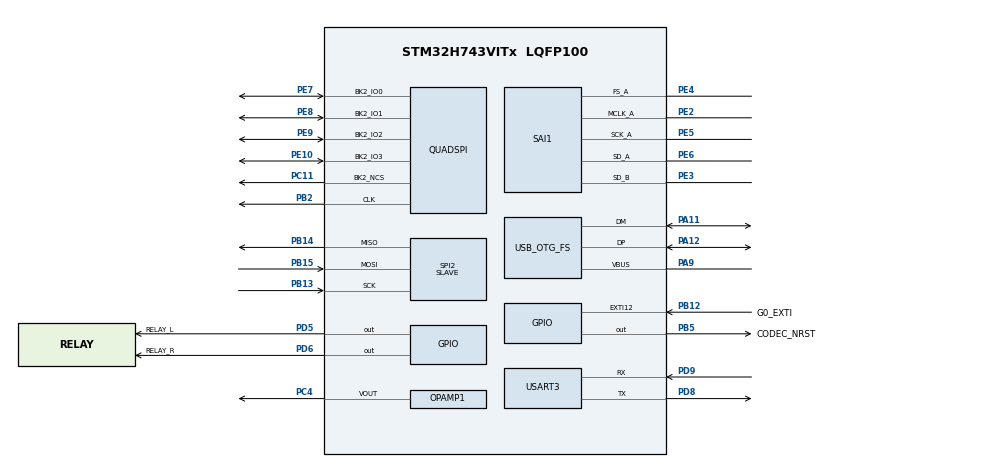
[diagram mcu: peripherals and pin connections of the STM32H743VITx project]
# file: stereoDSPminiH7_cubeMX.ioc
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CORTEX_M7.AccessPermission_S-Cortex_Memory_Protection_Unit_Region1_Settings_S=MPU_REGION_PRIV_RO
CORTEX_M7.AccessPermission_S-Cortex_Memory_Protection_Unit_Region2_Settings_S=MPU_REGION_FULL_ACCESS
CORTEX_M7.AccessPermission_S-Cortex_Memory_Protection_Unit_Region3_Settings_S=MPU_REGION_FULL_ACCESS
CORTEX_M7.BaseAddress_S-Cortex_Memory_Protection_Unit_Region1_Settings_S=0x08000000
CORTEX_M7.BaseAddress_S-Cortex_Memory_Protection_Unit_Region2_Settings_S=0x30046000
CORTEX_M7.BaseAddress_S-Cortex_Memory_Protection_Unit_Region3_Settings_S=0x90000000
CORTEX_M7.CPU_DCache=Enabled
CORTEX_M7.CPU_ICache=Enabled
CORTEX_M7.Enable_S-Cortex_Memory_Protection_Unit_Region1_Settings_S=MPU_REGION_ENABLE
CORTEX_M7.Enable_S-Cortex_Memory_Protection_Unit_Region2_Settings_S=MPU_REGION_ENABLE
CORTEX_M7.Enable_S-Cortex_Memory_Protection_Unit_Region3_Settings_S=MPU_REGION_ENABLE
CORTEX_M7.IsBufferable_S-Cortex_Memory_Protection_Unit_Region1_Settings_S=MPU_ACCESS_BUFFERABLE
CORTEX_M7.IsCacheable_S-Cortex_Memory_Protection_Unit_Region1_Settings_S=MPU_ACCESS_CACHEABLE
CORTEX_M7.Number_S-Cortex_Memory_Protection_Unit_Region2_Settings_S=MPU_REGION_NUMBER2
CORTEX_M7.Number_S-Cortex_Memory_Protection_Unit_Region3_Settings_S=MPU_REGION_NUMBER3
CORTEX_M7.Size_S-Cortex_Memory_Protection_Unit_Region1_Settings_S=MPU_REGION_SIZE_2MB
CORTEX_M7.Size_S-Cortex_Memory_Protection_Unit_Region2_Settings_S=MPU_REGION_SIZE_8KB
CORTEX_M7.Size_S-Cortex_Memory_Protection_Unit_Region3_Settings_S=MPU_REGION_SIZE_16MB
CORTEX_M7.TypeExtField_S-Cortex_Memory_Protection_Unit_Region1_Settings_S=MPU_TEX_LEVEL1
CORTEX_M7.TypeExtField_S-Cortex_Memory_Protection_Unit_Region2_Settings_S=MPU_TEX_LEVEL1
CORTEX_M7.TypeExtField_S-Cortex_Memory_Protection_Unit_Region3_Settings_S=MPU_TEX_LEVEL1
CORTEX_M7.default_mode_Activation=1
DAC1.DAC_Channel-DAC_OUT1_Int=DAC_CHANNEL_1
Dma.Request0=SAI1_A
Dma.Request1=SAI1_B
Dma.Request2=SPI2_RX
Dma.Request3=SPI2_TX
Dma.SAI1_A.0.Direction=DMA_MEMORY_TO_PERIPH
Dma.SAI1_A.0.EventEnable=DISABLE
Dma.SAI1_A.0.FIFOMode=DMA_FIFOMODE_ENABLE
Dma.SAI1_A.0.FIFOThreshold=DMA_FIFO_THRESHOLD_FULL
Dma.SAI1_A.0.Instance=DMA1_Stream0
Dma.SAI1_A.0.MemBurst=DMA_MBURST_INC4
Dma.SAI1_A.0.MemDataAlignment=DMA_MDATAALIGN_WORD
Dma.SAI1_A.0.MemInc=DMA_MINC_ENABLE
Dma.SAI1_A.0.Mode=DMA_CIRCULAR
Dma.SAI1_A.0.PeriphBurst=DMA_PBURST_INC4
Dma.SAI1_A.0.PeriphDataAlignment=DMA_PDATAALIGN_WORD
Dma.SAI1_A.0.PeriphInc=DMA_PINC_DISABLE
Dma.SAI1_A.0.Polarity=HAL_DMAMUX_REQ_GEN_RISING
Dma.SAI1_A.0.Priority=DMA_PRIORITY_VERY_HIGH
Dma.SAI1_A.0.RequestNumber=1
Dma.SAI1_A.0.SignalID=NONE
Dma.SAI1_A.0.SyncEnable=DISABLE
Dma.SAI1_A.0.SyncPolarity=HAL_DMAMUX_SYNC_NO_EVENT
Dma.SAI1_A.0.SyncRequestNumber=1
Dma.SAI1_A.0.SyncSignalID=NONE
Dma.SAI1_B.1.Direction=DMA_PERIPH_TO_MEMORY
Dma.SAI1_B.1.EventEnable=DISABLE
Dma.SAI1_B.1.FIFOMode=DMA_FIFOMODE_ENABLE
Dma.SAI1_B.1.FIFOThreshold=DMA_FIFO_THRESHOLD_FULL
Dma.SAI1_B.1.Instance=DMA1_Stream1
Dma.SAI1_B.1.MemBurst=DMA_MBURST_INC4
Dma.SAI1_B.1.MemDataAlignment=DMA_MDATAALIGN_WORD
Dma.SAI1_B.1.MemInc=DMA_MINC_ENABLE
Dma.SAI1_B.1.Mode=DMA_CIRCULAR
Dma.SAI1_B.1.PeriphBurst=DMA_PBURST_INC4
Dma.SAI1_B.1.PeriphDataAlignment=DMA_PDATAALIGN_WORD
Dma.SAI1_B.1.PeriphInc=DMA_PINC_DISABLE
Dma.SAI1_B.1.Polarity=HAL_DMAMUX_REQ_GEN_RISING
Dma.SAI1_B.1.Priority=DMA_PRIORITY_VERY_HIGH
Dma.SAI1_B.1.RequestNumber=1
Dma.SAI1_B.1.SignalID=NONE
Dma.SAI1_B.1.SyncEnable=DISABLE
Dma.SAI1_B.1.SyncPolarity=HAL_DMAMUX_SYNC_NO_EVENT
Dma.SAI1_B.1.SyncRequestNumber=1
Dma.SAI1_B.1.SyncSignalID=NONE
Dma.SPI2_RX.2.Direction=DMA_PERIPH_TO_MEMORY
Dma.SPI2_RX.2.EventEnable=DISABLE
Dma.SPI2_RX.2.FIFOMode=DMA_FIFOMODE_DISABLE
Dma.SPI2_RX.2.Instance=DMA2_Stream0
Dma.SPI2_RX.2.MemDataAlignment=DMA_MDATAALIGN_HALFWORD
Dma.SPI2_RX.2.MemInc=DMA_MINC_ENABLE
Dma.SPI2_RX.2.Mode=DMA_NORMAL
Dma.SPI2_RX.2.PeriphDataAlignment=DMA_PDATAALIGN_HALFWORD
Dma.SPI2_RX.2.PeriphInc=DMA_PINC_DISABLE
Dma.SPI2_RX.2.Polarity=HAL_DMAMUX_REQ_GEN_RISING
Dma.SPI2_RX.2.Priority=DMA_PRIORITY_VERY_HIGH
Dma.SPI2_RX.2.RequestNumber=1
Dma.SPI2_RX.2.SignalID=NONE
Dma.SPI2_RX.2.SyncEnable=DISABLE
Dma.SPI2_RX.2.SyncPolarity=HAL_DMAMUX_SYNC_NO_EVENT
Dma.SPI2_RX.2.SyncRequestNumber=1
Dma.SPI2_RX.2.SyncSignalID=NONE
Dma.SPI2_TX.3.Direction=DMA_MEMORY_TO_PERIPH
Dma.SPI2_TX.3.EventEnable=DISABLE
Dma.SPI2_TX.3.FIFOMode=DMA_FIFOMODE_DISABLE
Dma.SPI2_TX.3.Instance=DMA2_Stream1
Dma.SPI2_TX.3.MemDataAlignment=DMA_MDATAALIGN_HALFWORD
Dma.SPI2_TX.3.MemInc=DMA_MINC_ENABLE
Dma.SPI2_TX.3.Mode=DMA_NORMAL
Dma.SPI2_TX.3.PeriphDataAlignment=DMA_PDATAALIGN_HALFWORD
Dma.SPI2_TX.3.PeriphInc=DMA_PINC_DISABLE
Dma.SPI2_TX.3.Polarity=HAL_DMAMUX_REQ_GEN_RISING
Dma.SPI2_TX.3.Priority=DMA_PRIORITY_VERY_HIGH
Dma.SPI2_TX.3.RequestNumber=1
Dma.SPI2_TX.3.SignalID=NONE
Dma.SPI2_TX.3.SyncEnable=DISABLE
Dma.SPI2_TX.3.SyncPolarity=HAL_DMAMUX_SYNC_NO_EVENT
Dma.SPI2_TX.3.SyncRequestNumber=1
Dma.SPI2_TX.3.SyncSignalID=NONE
Mcu.Family=STM32H7
Mcu.Name=STM32H743VITx
Mcu.Package=LQFP100
NVIC.DMA1_Stream0_IRQn=true\:0\:0\:true\:false\:true\:false\:true\:true
NVIC.DMA1_Stream1_IRQn=true\:0\:0\:false\:false\:true\:false\:true\:true
NVIC.DMA2_Stream0_IRQn=true\:2\:0\:true\:false\:true\:false\:true\:true
NVIC.DMA2_Stream1_IRQn=true\:2\:0\:true\:false\:true\:false\:true\:true
NVIC.EXTI15_10_IRQn=true\:2\:0\:true\:false\:true\:true\:true\:true
NVIC.OTG_FS_EP1_IN_IRQn=true\:0\:0\:false\:false\:true\:true\:true\:true
NVIC.OTG_FS_EP1_OUT_IRQn=true\:0\:0\:false\:false\:true\:true\:true\:true
NVIC.OTG_FS_IRQn=true\:0\:0\:false\:false\:true\:false\:true\:true
NVIC.PriorityGroup=NVIC_PRIORITYGROUP_4
NVIC.SAI1_IRQn=true\:1\:0\:true\:false\:true\:true\:true\:true
NVIC.SPI2_IRQn=true\:2\:0\:true\:false\:true\:false\:true\:true
PA11.Mode=Device_Only
PA11.Signal=USB_OTG_FS_DM
PA12.Mode=Device_Only
PA12.Signal=USB_OTG_FS_DP
PA13\ (JTMS/SWDIO).Mode=Trace_Asynchronous_SW
PA13\ (JTMS/SWDIO).Signal=DEBUG_JTMS-SWDIO
PA14\ (JTCK/SWCLK).Mode=Trace_Asynchronous_SW
PA14\ (JTCK/SWCLK).Signal=DEBUG_JTCK-SWCLK
PA9.Mode=Activate_VBUS
PA9.Signal=USB_OTG_FS_VBUS
PB12.GPIO_Label=G0_EXTI
PB12.Signal=GPXTI12
PB13.Mode=Full_Duplex_Slave
PB13.Signal=SPI2_SCK
PB14.Mode=Full_Duplex_Slave
PB14.Signal=SPI2_MISO
PB15.Mode=Full_Duplex_Slave
PB15.Signal=SPI2_MOSI
PB2.GPIO_Speed=GPIO_SPEED_FREQ_HIGH
PB2.Mode=Single Bank 2
PB2.Signal=QUADSPI_CLK
PB3\ (JTDO/TRACESWO).Mode=Trace_Asynchronous_SW
PB3\ (JTDO/TRACESWO).Signal=DEBUG_JTDO-SWO
PB5.GPIO_Label=CODEC_NRST
PB5.Signal=GPIO_Output
PC11.GPIO_PuPd=GPIO_PULLUP
PC11.GPIO_Speed=GPIO_SPEED_FREQ_MEDIUM
PC11.Mode=Single Bank 2
PC11.Signal=QUADSPI_BK2_NCS
PC4.Mode=Follower-DAC_OUT1-INP
PC4.Signal=OPAMP1_VOUT
PD5.GPIO_Label=RELAY_L
PD5.Signal=GPIO_Output
PD6.GPIO_Label=RELAY_R
PD6.Signal=GPIO_Output
PD8.Mode=Asynchronous
PD8.Signal=USART3_TX
PD9.GPIO_PuPd=GPIO_PULLUP
PD9.Mode=Asynchronous
PD9.Signal=USART3_RX
PE10.GPIO_Speed=GPIO_SPEED_FREQ_HIGH
PE10.Mode=Single Bank 2
PE10.Signal=QUADSPI_BK2_IO3
PE2.Mode=SAI_A_MasterWithClock
PE2.Signal=SAI1_MCLK_A
PE3.Mode=SAI_B_SyncSlave
PE3.Signal=SAI1_SD_B
PE4.Mode=SAI_A_MasterWithClock
PE4.Signal=SAI1_FS_A
PE5.Mode=SAI_A_MasterWithClock
PE5.Signal=SAI1_SCK_A
PE6.Mode=SAI_A_MasterWithClock
PE6.Signal=SAI1_SD_A
PE7.GPIO_Speed=GPIO_SPEED_FREQ_HIGH
PE7.Mode=Single Bank 2
PE7.Signal=QUADSPI_BK2_IO0
PE8.GPIO_Speed=GPIO_SPEED_FREQ_HIGH
PE8.Mode=Single Bank 2
PE8.Signal=QUADSPI_BK2_IO1
PE9.GPIO_Speed=GPIO_SPEED_FREQ_HIGH
PE9.Mode=Single Bank 2
PE9.Signal=QUADSPI_BK2_IO2
PH0-OSC_IN\ (PH0).Mode=HSE-External-Oscillator
PH0-OSC_IN\ (PH0).Signal=RCC_OSC_IN
PH1-OSC_OUT\ (PH1).Mode=HSE-External-Oscillator
PH1-OSC_OUT\ (PH1).Signal=RCC_OSC_OUT
ProjectManager.HeapSize=0x200
ProjectManager.StackSize=0x400
ProjectManager.TargetToolchain=CMake
QUADSPI.ClockPrescaler=1
QUADSPI.FlashSize=23
RCC.ADCFreq_Value=24615384.615384616
RCC.APB1Freq_Value=120000000
RCC.APB2Freq_Value=120000000
RCC.APB3Freq_Value=120000000
RCC.APB4Freq_Value=120000000
RCC.CortexFreq_Value=60000000
RCC.Cortex_Div=SYSTICK_CLKSOURCE_HCLK_DIV8
RCC.D1PPRE=RCC_APB3_DIV2
RCC.D2PPRE1=RCC_APB1_DIV2
RCC.D2PPRE2=RCC_APB2_DIV2
RCC.D3PPRE=RCC_APB4_DIV2
RCC.DIVM1=1
RCC.DIVM2=1
RCC.DIVM3=1
RCC.DIVN1=60
RCC.DIVN2=60
RCC.DIVN3=16
RCC.DIVP2=39
RCC.DIVP3=4
RCC.DIVQ1=20
RCC.DIVQ2=4
RCC.DIVQ3=4
RCC.DIVR2=4
RCC.HCLKFreq_Value=240000000
RCC.HPRE=RCC_HCLK_DIV2
RCC.HSE_VALUE=16000000
RCC.PLL2FRACN=0
RCC.PLL3FRACN=0
RCC.PLLFRACN=0
RCC.RNGCLockSelection=RCC_RNGCLKSOURCE_PLL
RCC.SAI1CLockSelection=RCC_SAI1CLKSOURCE_PLL2
RCC.SPI123CLockSelection=RCC_SPI123CLKSOURCE_PLL3
RCC.SYSCLKFreq_VALUE=480000000
RCC.SYSCLKSource=RCC_SYSCLKSOURCE_PLLCLK
RCC.USART234578CLockSelection=RCC_USART234578CLKSOURCE_PLL3
RCC.USBFreq_Value=48000000
SAI1.ActiveFrameLength-SAI_A_MasterWithClock=32
SAI1.ActiveFrameLength-SAI_B_SyncSlave=32
SAI1.AudioFrequency-SAI_A_MasterWithClock=SAI_AUDIO_FREQUENCY_48K
SAI1.AudioMode-SAI_B_SyncSlave=SAI_MODESLAVE_RX
SAI1.ClockSource-SAI_A_MasterWithClock=SAI_CLKSOURCE_PLLSAI
SAI1.DataSize-SAI_A_MasterWithClock=SAI_DATASIZE_24
SAI1.DataSize-SAI_B_SyncSlave=SAI_DATASIZE_24
SAI1.ErrorAudioFreq-SAI_A_MasterWithClock=0.15 %
SAI1.FIFOThreshold-SAI_A_MasterWithClock=SAI_FIFOTHRESHOLD_HF
SAI1.FIFOThreshold-SAI_B_SyncSlave=SAI_FIFOTHRESHOLD_HF
SAI1.FSOffset-SAI_A_MasterWithClock=SAI_FS_BEFOREFIRSTBIT
SAI1.FSOffset-SAI_B_SyncSlave=SAI_FS_BEFOREFIRSTBIT
SAI1.FirstBitOffset-SAI_A_MasterWithClock=0
SAI1.FirstBitOffset-SAI_B_SyncSlave=0
SAI1.FrameLength-SAI_A_MasterWithClock=64
SAI1.FrameLength-SAI_B_SyncSlave=64
SAI1.Instance-SAI_A_MasterWithClock=SAI$Index_Block_A
SAI1.Instance-SAI_B_SyncSlave=SAI$Index_Block_B
SAI1.MClockEnable=SAI_MASTERCLOCK_ENABLE
SAI1.MckOverSampling-SAI_A_MasterWithClock=SAI_MCK_OVERSAMPLING_ENABLE
SAI1.MckOverSampling-SAI_B_SyncSlave=SAI_MCK_OVERSAMPLING_ENABLE
SAI1.MonoStereoMode-SAI_B_SyncSlave=SAI_STEREOMODE
SAI1.NoDivider-SAI_A_MasterWithClock=SAI_MASTERDIVIDER_ENABLE
SAI1.RealAudioFreq-SAI_A_MasterWithClock=48.076 KHz
SAI1.SlotActive-SAI_A_MasterWithClock=0x0000FFFF
SAI1.SlotActive-SAI_B_SyncSlave=0x0000FFFF
SAI1.SlotNumber-SAI_A_MasterWithClock=2
SAI1.SlotNumber-SAI_B_SyncSlave=2
SAI1.SlotSize-SAI_A_MasterWithClock=SAI_SLOTSIZE_32B
SAI1.SlotSize-SAI_B_SyncSlave=SAI_SLOTSIZE_32B
SAI1.Synchro_B=SAI_SYNCHRONOUS
SAI1.VirtualMode-SAI_A_MasterWithClock=VM_MASTER
SAI1.VirtualMode-SAI_B_SyncSlave=VM_SLAVE
SAI1.VirtualSlotActive-SAI_A_MasterWithClock=SAI_SLOTACTIVE_ALL
SAI1.VirtualSlotActive-SAI_B_SyncSlave=SAI_SLOTACTIVE_ALL
SPI2.CRCCalculation=SPI_CRCCALCULATION_ENABLE
SPI2.CRCLength=SPI_CRC_LENGTH_16BIT
SPI2.CRCPolynomial=0x11021
SPI2.DataSize=SPI_DATASIZE_16BIT
SPI2.Direction=SPI_DIRECTION_2LINES
SPI2.FifoThreshold=SPI_FIFO_THRESHOLD_01DATA
SPI2.Mode=SPI_MODE_SLAVE
SPI2.VirtualType=VM_SLAVE
USART3.Parity=PARITY_EVEN
USART3.VirtualMode-Asynchronous=VM_ASYNC
USART3.WordLength=WORDLENGTH_9B
USB_DEVICE.CLASS_NAME_FS=MSC
USB_DEVICE.MANUFACTURER_STRING-MSC_FS=Downing Audio Designs
USB_DEVICE.MSC_MEDIA_PACKET-MSC_FS=4096
USB_DEVICE.VirtualMode-MSC_FS=Msc
USB_DEVICE.VirtualModeFS=Msc_FS
USB_OTG_FS.VirtualMode=Device_Only
USB_OTG_FS.lpm_enable=DISABLE
VP_DAC1_VS_DACI1.Mode=DAC_OUT1_Int
VP_MEMORYMAP_VS_MEMORYMAP.Mode=CurAppReg
VP_RNG_VS_RNG.Mode=RNG_Activate
VP_USB_DEVICE_VS_USB_DEVICE_MSC_FS.Mode=MSC_FS
board=custom

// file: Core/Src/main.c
/* USER CODE BEGIN Header */
/**
  ******************************************************************************
  * @file           : main.c
  * @brief          : Main program body
  ******************************************************************************
  * @attention
  *
  * Copyright (c) 2026 STMicroelectronics.
  * All rights reserved.
  *
  * This software is licensed under terms that can be found in the LICENSE file
  * in the root directory of this software component.
  * If no LICENSE file comes with this software, it is provided AS-IS.
  *
  ******************************************************************************
  */
/* USER CODE END Header */
#include "main.h"
#include "dac.h"
#include "dma.h"
#include "opamp.h"
#include "quadspi.h"
#include "rng.h"
#include "sai.h"
#include "spi.h"
#include "usart.h"
#include "usb_device.h"
#include "gpio.h"

/* USER CODE BEGIN Includes */
#include "w25q_mem.h"
#include <string.h>
/* USER CODE END Includes */

void SystemClock_Config(void);
void PeriphCommonClock_Config(void);
static void MPU_Config(void);
/* USER CODE BEGIN PFP */
void App_Run(void);
/* USER CODE END PFP */

int main(void)
{

  /* MPU Configuration--------------------------------------------------------*/
  MPU_Config();

  /* Enable the CPU Cache */

  /* Enable I-Cache---------------------------------------------------------*/
  SCB_EnableICache();

  /* Enable D-Cache---------------------------------------------------------*/
  SCB_EnableDCache();

  /* MCU Configuration--------------------------------------------------------*/

  /* Reset of all peripherals, Initializes the Flash interface and the Systick. */
  HAL_Init();

  /* Configure the system clock */
  SystemClock_Config();

  /* Configure the peripherals common clocks */
  PeriphCommonClock_Config();

  /* Initialize all configured peripherals */
  MX_GPIO_Init();
  MX_DMA_Init();
  MX_DAC1_Init();
  MX_SPI2_Init();
  MX_USB_DEVICE_Init();
  MX_SAI1_Init();
  MX_QUADSPI_Init();
  MX_RNG_Init();
  MX_USART3_UART_Init();
  MX_OPAMP1_Init();
  /* USER CODE BEGIN 2 */

  W25Q_STATE extFlash = W25Q_Init();
  if (extFlash != W25Q_OK)
  {
    Error_Handler();
  }

  App_Run();
  /* USER CODE END 2 */

  /* Infinite loop */
  /* USER CODE BEGIN WHILE */
  // Never reached
  while (1)
  {
    /* USER CODE END WHILE */

  }
}

void SystemClock_Config(void)
{
  RCC_OscInitTypeDef RCC_OscInitStruct = {0};
  RCC_ClkInitTypeDef RCC_ClkInitStruct = {0};

  /** Supply configuration update enable
  */
  HAL_PWREx_ConfigSupply(PWR_LDO_SUPPLY);

  /** Configure the main internal regulator output voltage
  */
  __HAL_PWR_VOLTAGESCALING_CONFIG(PWR_REGULATOR_VOLTAGE_SCALE0);

  while(!__HAL_PWR_GET_FLAG(PWR_FLAG_VOSRDY)) {}

  /** Initializes the RCC Oscillators according to the specified parameters
  * in the RCC_OscInitTypeDef structure.
  */
  RCC_OscInitStruct.OscillatorType = RCC_OSCILLATORTYPE_HSE;
  RCC_OscInitStruct.HSEState = RCC_HSE_ON;
  RCC_OscInitStruct.PLL.PLLState = RCC_PLL_ON;
  RCC_OscInitStruct.PLL.PLLSource = RCC_PLLSOURCE_HSE;
  RCC_OscInitStruct.PLL.PLLM = 1;
  RCC_OscInitStruct.PLL.PLLN = 60;
  RCC_OscInitStruct.PLL.PLLP = 2;
  RCC_OscInitStruct.PLL.PLLQ = 20;
  RCC_OscInitStruct.PLL.PLLR = 2;
  RCC_OscInitStruct.PLL.PLLRGE = RCC_PLL1VCIRANGE_3;
  RCC_OscInitStruct.PLL.PLLVCOSEL = RCC_PLL1VCOWIDE;
  RCC_OscInitStruct.PLL.PLLFRACN = 0;
  if (HAL_RCC_OscConfig(&RCC_OscInitStruct) != HAL_OK)
  {
    Error_Handler();
  }

  /** Initializes the CPU, AHB and APB buses clocks
  */
  RCC_ClkInitStruct.ClockType = RCC_CLOCKTYPE_HCLK|RCC_CLOCKTYPE_SYSCLK
                              |RCC_CLOCKTYPE_PCLK1|RCC_CLOCKTYPE_PCLK2
                              |RCC_CLOCKTYPE_D3PCLK1|RCC_CLOCKTYPE_D1PCLK1;
  RCC_ClkInitStruct.SYSCLKSource = RCC_SYSCLKSOURCE_PLLCLK;
  RCC_ClkInitStruct.SYSCLKDivider = RCC_SYSCLK_DIV1;
  RCC_ClkInitStruct.AHBCLKDivider = RCC_HCLK_DIV2;
  RCC_ClkInitStruct.APB3CLKDivider = RCC_APB3_DIV2;
  RCC_ClkInitStruct.APB1CLKDivider = RCC_APB1_DIV2;
  RCC_ClkInitStruct.APB2CLKDivider = RCC_APB2_DIV2;
  RCC_ClkInitStruct.APB4CLKDivider = RCC_APB4_DIV2;

  if (HAL_RCC_ClockConfig(&RCC_ClkInitStruct, FLASH_LATENCY_4) != HAL_OK)
  {
    Error_Handler();
  }
}

void PeriphCommonClock_Config(void)
{
  RCC_PeriphCLKInitTypeDef PeriphClkInitStruct = {0};

  /** Initializes the peripherals clock
  */
  PeriphClkInitStruct.PeriphClockSelection = RCC_PERIPHCLK_SAI1|RCC_PERIPHCLK_SPI2
                              |RCC_PERIPHCLK_USART3;
  PeriphClkInitStruct.PLL2.PLL2M = 1;
  PeriphClkInitStruct.PLL2.PLL2N = 60;
  PeriphClkInitStruct.PLL2.PLL2P = 39;
  PeriphClkInitStruct.PLL2.PLL2Q = 4;
  PeriphClkInitStruct.PLL2.PLL2R = 4;
  PeriphClkInitStruct.PLL2.PLL2RGE = RCC_PLL2VCIRANGE_3;
  PeriphClkInitStruct.PLL2.PLL2VCOSEL = RCC_PLL2VCOWIDE;
  PeriphClkInitStruct.PLL2.PLL2FRACN = 0;
  PeriphClkInitStruct.PLL3.PLL3M = 1;
  PeriphClkInitStruct.PLL3.PLL3N = 16;
  PeriphClkInitStruct.PLL3.PLL3P = 4;
  PeriphClkInitStruct.PLL3.PLL3Q = 4;
  PeriphClkInitStruct.PLL3.PLL3R = 2;
  PeriphClkInitStruct.PLL3.PLL3RGE = RCC_PLL3VCIRANGE_3;
  PeriphClkInitStruct.PLL3.PLL3VCOSEL = RCC_PLL3VCOWIDE;
  PeriphClkInitStruct.PLL3.PLL3FRACN = 0;
  PeriphClkInitStruct.Sai1ClockSelection = RCC_SAI1CLKSOURCE_PLL2;
  PeriphClkInitStruct.Spi123ClockSelection = RCC_SPI123CLKSOURCE_PLL3;
  PeriphClkInitStruct.Usart234578ClockSelection = RCC_USART234578CLKSOURCE_PLL3;
  if (HAL_RCCEx_PeriphCLKConfig(&PeriphClkInitStruct) != HAL_OK)
  {
    Error_Handler();
  }
}

 /* MPU Configuration */

void MPU_Config(void)
{
  MPU_Region_InitTypeDef MPU_InitStruct = {0};

  /* Disables the MPU */
  HAL_MPU_Disable();

  /** Initializes and configures the Region and the memory to be protected
  */
  MPU_InitStruct.Enable = MPU_REGION_ENABLE;
  MPU_InitStruct.Number = MPU_REGION_NUMBER0;
  MPU_InitStruct.BaseAddress = 0x0;
  MPU_InitStruct.Size = MPU_REGION_SIZE_4GB;
  MPU_InitStruct.SubRegionDisable = 0x87;
  MPU_InitStruct.TypeExtField = MPU_TEX_LEVEL0;
  MPU_InitStruct.AccessPermission = MPU_REGION_NO_ACCESS;
  MPU_InitStruct.DisableExec = MPU_INSTRUCTION_ACCESS_DISABLE;
  MPU_InitStruct.IsShareable = MPU_ACCESS_SHAREABLE;
  MPU_InitStruct.IsCacheable = MPU_ACCESS_NOT_CACHEABLE;
  MPU_InitStruct.IsBufferable = MPU_ACCESS_NOT_BUFFERABLE;

  HAL_MPU_ConfigRegion(&MPU_InitStruct);

  /** Initializes and configures the Region and the memory to be protected
  */
  MPU_InitStruct.Number = MPU_REGION_NUMBER1;
  MPU_InitStruct.BaseAddress = 0x08000000;
  MPU_InitStruct.Size = MPU_REGION_SIZE_2MB;
  MPU_InitStruct.SubRegionDisable = 0x0;
  MPU_InitStruct.TypeExtField = MPU_TEX_LEVEL1;
  MPU_InitStruct.AccessPermission = MPU_REGION_PRIV_RO;
  MPU_InitStruct.DisableExec = MPU_INSTRUCTION_ACCESS_ENABLE;
  MPU_InitStruct.IsShareable = MPU_ACCESS_NOT_SHAREABLE;
  MPU_InitStruct.IsCacheable = MPU_ACCESS_CACHEABLE;
  MPU_InitStruct.IsBufferable = MPU_ACCESS_BUFFERABLE;

  HAL_MPU_ConfigRegion(&MPU_InitStruct);

  /** Initializes and configures the Region and the memory to be protected
  */
  MPU_InitStruct.Number = MPU_REGION_NUMBER2;
  MPU_InitStruct.BaseAddress = 0x30046000;
  MPU_InitStruct.Size = MPU_REGION_SIZE_8KB;
  MPU_InitStruct.AccessPermission = MPU_REGION_FULL_ACCESS;
  MPU_InitStruct.IsCacheable = MPU_ACCESS_NOT_CACHEABLE;
  MPU_InitStruct.IsBufferable = MPU_ACCESS_NOT_BUFFERABLE;

  HAL_MPU_ConfigRegion(&MPU_InitStruct);

  /** Initializes and configures the Region and the memory to be protected
  */
  MPU_InitStruct.Number = MPU_REGION_NUMBER3;
  MPU_InitStruct.BaseAddress = 0x90000000;
  MPU_InitStruct.Size = MPU_REGION_SIZE_16MB;

  HAL_MPU_ConfigRegion(&MPU_InitStruct);
  /* Enables the MPU */
  HAL_MPU_Enable(MPU_PRIVILEGED_DEFAULT);

}

void Error_Handler(void)
{
  __disable_irq();
  while (1)
  {
  }
}
